# LM3S1150 register map
File version: 7944
Registers are 32-bit, read-write, no defined reset value unless marked. A register's access mark holds for its fields unless they carry their own. Offsets are from the block's base; [hi:lo] are bit positions; {n}, {i} and the like mark numbered series.

## QEI0 — Register map for QEI0 peripheral
Base 0x4002C000; register names take the prefix QEI0
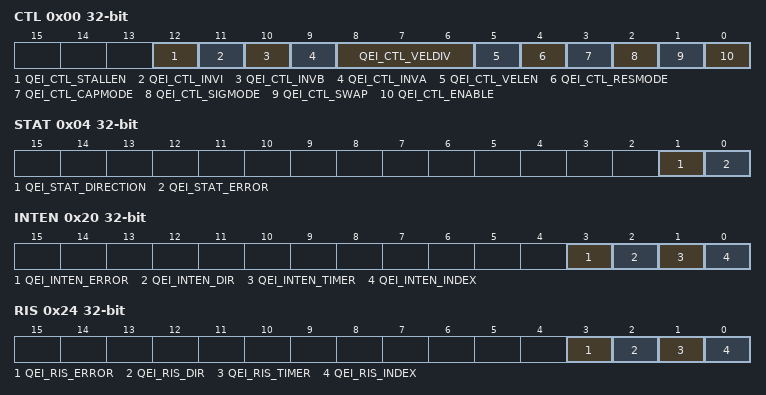
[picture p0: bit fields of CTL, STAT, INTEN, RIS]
0x00 CTL — QEI Control
  [12] QEI_CTL_STALLEN — Stall QEI
  [11] QEI_CTL_INVI — Invert Index Pulse
  [10] QEI_CTL_INVB — Invert PhB
  [9] QEI_CTL_INVA — Invert PhA
  [8:6] QEI_CTL_VELDIV — Predivide Velocity
    0=QEI clock /1; 1=QEI clock /2; 2=QEI clock /4; 3=QEI clock /8; 4=QEI clock /16; 5=QEI clock /32; 6=QEI clock /64; 7=QEI clock /128
  [5] QEI_CTL_VELEN — Capture Velocity
  [4] QEI_CTL_RESMODE — Reset Mode
  [3] QEI_CTL_CAPMODE — Capture Mode
  [2] QEI_CTL_SIGMODE — Signal Mode
  [1] QEI_CTL_SWAP — Swap Signals
  [0] QEI_CTL_ENABLE — Enable QEI
0x04 STAT — QEI Status
  [1] QEI_STAT_DIRECTION — Direction of Rotation
  [0] QEI_STAT_ERROR — Error Detected
0x08 POS — QEI Position
  [31:0] QEI_POS — Current Position Integrator Value
0x0C MAXPOS — QEI Maximum Position
  [31:0] QEI_MAXPOS — Maximum Position Integrator Value
0x10 LOAD — QEI Timer Load
  [31:0] QEI_LOAD — Velocity Timer Load Value
0x14 TIME — QEI Timer
  [31:0] QEI_TIME — Velocity Timer Current Value
0x18 COUNT — QEI Velocity Counter
  [31:0] QEI_COUNT — Velocity Pulse Count
0x1C SPEED — QEI Velocity
  [31:0] QEI_SPEED — Velocity
0x20 INTEN — QEI Interrupt Enable
  [3] QEI_INTEN_ERROR — Phase Error Interrupt Enable
  [2] QEI_INTEN_DIR — Direction Change Interrupt Enable
  [1] QEI_INTEN_TIMER — Timer Expires Interrupt Enable
  [0] QEI_INTEN_INDEX — Index Pulse Detected Interrupt Enable
0x24 RIS — QEI Raw Interrupt Status
  [3] QEI_RIS_ERROR — Phase Error Detected
  [2] QEI_RIS_DIR — Direction Change Detected
  [1] QEI_RIS_TIMER — Velocity Timer Expired
  [0] QEI_RIS_INDEX — Index Pulse Asserted
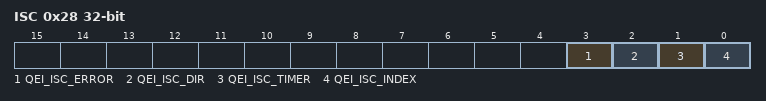
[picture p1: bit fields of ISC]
0x28 ISC — QEI Interrupt Status and Clear
  [3] QEI_ISC_ERROR — Phase Error Interrupt
  [2] QEI_ISC_DIR — Direction Change Interrupt
  [1] QEI_ISC_TIMER — Velocity Timer Expired Interrupt
  [0] QEI_ISC_INDEX — Index Pulse Interrupt

## COMP — Register map for COMP peripheral
Base 0x4003C000; register names take the prefix COMP
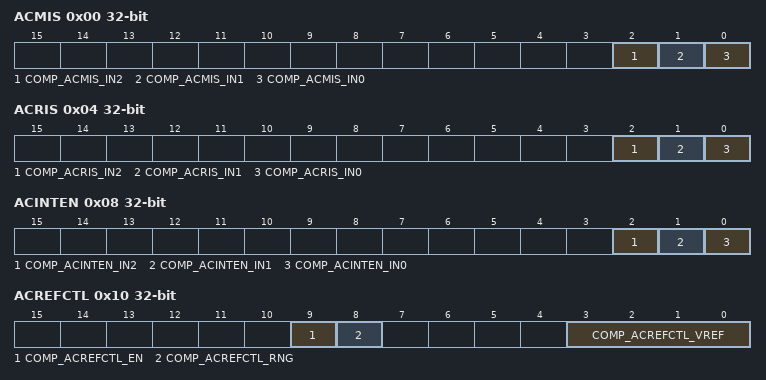
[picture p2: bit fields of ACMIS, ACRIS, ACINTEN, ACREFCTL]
0x00 ACMIS — Analog Comparator Masked Interrupt Status
  [2] COMP_ACMIS_IN2 — Comparator 2 Masked Interrupt Status
  [1] COMP_ACMIS_IN1 — Comparator 1 Masked Interrupt Status
  [0] COMP_ACMIS_IN0 — Comparator 0 Masked Interrupt Status
0x04 ACRIS — Analog Comparator Raw Interrupt Status
  [2] COMP_ACRIS_IN2 — Comparator 2 Interrupt Status
  [1] COMP_ACRIS_IN1 — Comparator 1 Interrupt Status
  [0] COMP_ACRIS_IN0 — Comparator 0 Interrupt Status
0x08 ACINTEN — Analog Comparator Interrupt Enable
  [2] COMP_ACINTEN_IN2 — Comparator 2 Interrupt Enable
  [1] COMP_ACINTEN_IN1 — Comparator 1 Interrupt Enable
  [0] COMP_ACINTEN_IN0 — Comparator 0 Interrupt Enable
0x10 ACREFCTL — Analog Comparator Reference Voltage Control
  [9] COMP_ACREFCTL_EN — Resistor Ladder Enable
  [8] COMP_ACREFCTL_RNG — Resistor Ladder Range
  [3:0] COMP_ACREFCTL_VREF — Resistor Ladder Voltage Ref
{0x20+0x20*i} ACSTAT{i} (i=0..2) — Analog Comparator Status {i}
  [1] COMP_ACSTAT{i}_OVAL — Comparator Output Value
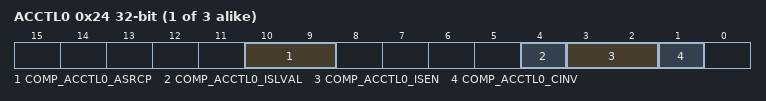
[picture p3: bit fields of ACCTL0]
{0x24+0x20*i} ACCTL{i} (i=0..2) — Analog Comparator Control {i}
  [10:9] COMP_ACCTL{i}_ASRCP — Analog Source Positive
    0=COMP_ACCTL{i}_ASRCP_PIN (Pin value of Cn+); 1=COMP_ACCTL{i}_ASRCP_PIN0 (Pin value of C0+); 2=COMP_ACCTL{i}_ASRCP_REF (Internal voltage reference (VIREF))
  [4] COMP_ACCTL{i}_ISLVAL — Interrupt Sense Level Value
  [3:2] COMP_ACCTL{i}_ISEN — Interrupt Sense
    0=COMP_ACCTL{i}_ISEN_LEVEL (Level sense, see ISLVAL); 1=COMP_ACCTL{i}_ISEN_FALL (Falling edge); 2=COMP_ACCTL{i}_ISEN_RISE (Rising edge); 3=COMP_ACCTL{i}_ISEN_BOTH (Either edge)
  [1] COMP_ACCTL{i}_CINV — Comparator Output Invert

## HIB — Register map for HIB peripheral
Base 0x400FC000; register names take the prefix HIB
0x00 RTCC — Hibernation RTC Counter
  [31:0] HIB_RTCC — RTC Counter
0x04 RTCM0 — Hibernation RTC Match 0
  [31:0] HIB_RTCM0 — RTC Match 0
0x08 RTCM1 — Hibernation RTC Match 1
  [31:0] HIB_RTCM1 — RTC Match 1
0x0C RTCLD — Hibernation RTC Load
  [31:0] HIB_RTCLD — RTC Load
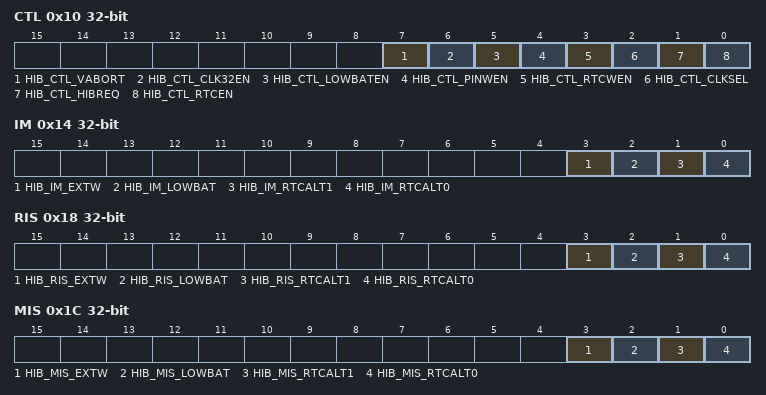
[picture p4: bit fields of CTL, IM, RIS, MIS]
0x10 CTL — Hibernation Control
  [7] HIB_CTL_VABORT — Power Cut Abort Enable
  [6] HIB_CTL_CLK32EN — Clocking Enable
  [5] HIB_CTL_LOWBATEN — Low Battery Monitoring Enable
  [4] HIB_CTL_PINWEN — External WAKE Pin Enable
  [3] HIB_CTL_RTCWEN — RTC Wake-up Enable
  [2] HIB_CTL_CLKSEL — Hibernation Module Clock Select
  [1] HIB_CTL_HIBREQ — Hibernation Request
  [0] HIB_CTL_RTCEN — RTC Timer Enable
0x14 IM — Hibernation Interrupt Mask
  [3] HIB_IM_EXTW — External Wake-Up Interrupt Mask
  [2] HIB_IM_LOWBAT — Low Battery Voltage Interrupt Mask
  [1] HIB_IM_RTCALT1 — RTC Alert 1 Interrupt Mask
  [0] HIB_IM_RTCALT0 — RTC Alert 0 Interrupt Mask
0x18 RIS — Hibernation Raw Interrupt Status
  [3] HIB_RIS_EXTW — External Wake-Up Raw Interrupt Status
  [2] HIB_RIS_LOWBAT — Low Battery Voltage Raw Interrupt Status
  [1] HIB_RIS_RTCALT1 — RTC Alert 1 Raw Interrupt Status
  [0] HIB_RIS_RTCALT0 — RTC Alert 0 Raw Interrupt Status
0x1C MIS — Hibernation Masked Interrupt Status
  [3] HIB_MIS_EXTW — External Wake-Up Masked Interrupt Status
  [2] HIB_MIS_LOWBAT — Low Battery Voltage Masked Interrupt Status
  [1] HIB_MIS_RTCALT1 — RTC Alert 1 Masked Interrupt Status
  [0] HIB_MIS_RTCALT0 — RTC Alert 0 Masked Interrupt Status
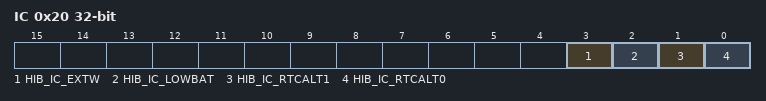
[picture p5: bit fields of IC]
0x20 IC — Hibernation Interrupt Clear
  [3] HIB_IC_EXTW — External Wake-Up Masked Interrupt Clear
  [2] HIB_IC_LOWBAT — Low Battery Voltage Masked Interrupt Clear
  [1] HIB_IC_RTCALT1 — RTC Alert1 Masked Interrupt Clear
  [0] HIB_IC_RTCALT0 — RTC Alert0 Masked Interrupt Clear
0x24 RTCT — Hibernation RTC Trim
  [15:0] HIB_RTCT_TRIM — RTC Trim Value
0x30 DATA — Hibernation Data
  [31:0] HIB_DATA_RTD — Hibernation Module NV Data

## FLASH_CTRL — Register map for FLASH_CTRL peripheral
Base 0x400FD000; register names take the prefix FLASH_CTRL
0x00 FMA — Flash Memory Address
  [15:0] FLASH_FMA_OFFSET — Address Offset
0x04 FMD — Flash Memory Data
  [31:0] FLASH_FMD_DATA — Data Value
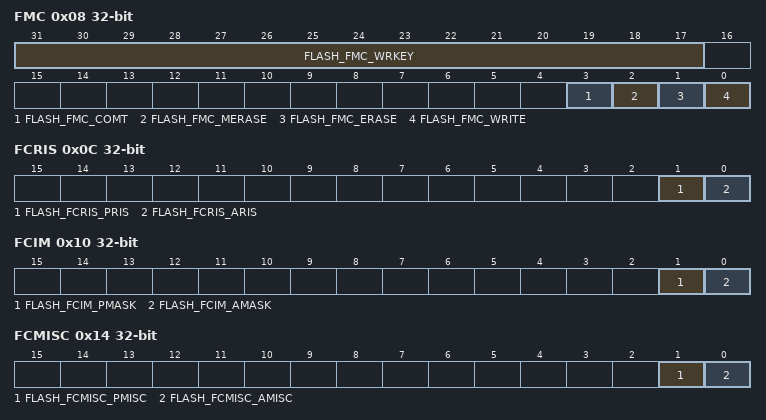
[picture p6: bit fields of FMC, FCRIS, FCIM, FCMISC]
0x08 FMC — Flash Memory Control
  [31:17] FLASH_FMC_WRKEY — FLASH write key
  [3] FLASH_FMC_COMT — Commit Register Value
  [2] FLASH_FMC_MERASE — Mass Erase Flash Memory
  [1] FLASH_FMC_ERASE — Erase a Page of Flash Memory
  [0] FLASH_FMC_WRITE — Write a Word into Flash Memory
0x0C FCRIS — Flash Controller Raw Interrupt Status
  [1] FLASH_FCRIS_PRIS — Programming Raw Interrupt Status
  [0] FLASH_FCRIS_ARIS — Access Raw Interrupt Status
0x10 FCIM — Flash Controller Interrupt Mask
  [1] FLASH_FCIM_PMASK — Programming Interrupt Mask
  [0] FLASH_FCIM_AMASK — Access Interrupt Mask
0x14 FCMISC — Flash Controller Masked Interrupt Status and Clear
  [1] FLASH_FCMISC_PMISC — Programming Masked Interrupt Status and Clear
  [0] FLASH_FCMISC_AMISC — Access Masked Interrupt Status and Clear
0x1140 USECRL — USec Reload
  [7:0] FLASH_USECRL — Microsecond Reload Value
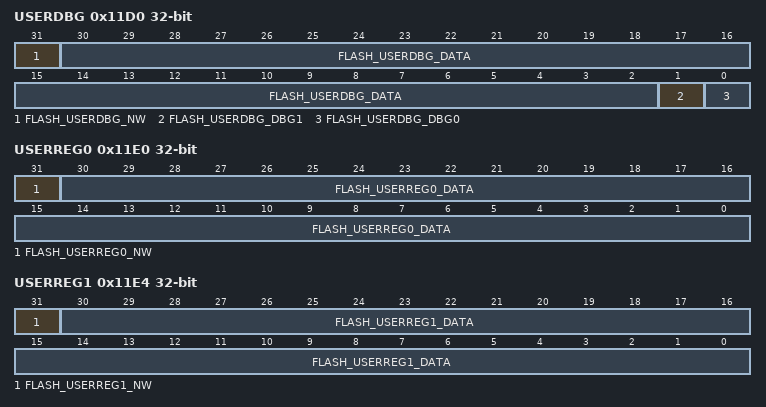
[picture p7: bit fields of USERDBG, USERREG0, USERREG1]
0x11D0 USERDBG (FLASH_ALT view) — User Debug
  [31] FLASH_USERDBG_NW — User Debug Not Written
  [30:2] FLASH_USERDBG_DATA — User Data
  [1] FLASH_USERDBG_DBG1 — Debug Control 1
  [0] FLASH_USERDBG_DBG0 — Debug Control 0
0x11E0 USERREG0 — User Register 0
  [31] FLASH_USERREG0_NW — Not Written
  [30:0] FLASH_USERREG0_DATA — User Data
0x11E4 USERREG1 — User Register 1
  [31] FLASH_USERREG1_NW — Not Written
  [30:0] FLASH_USERREG1_DATA — User Data
{0x1200+4i} FMPRE{i} (i=0..3) — Flash Memory Protection Read Enable {i}
{0x1400+4i} FMPPE{i} (i=0..3) — Flash Memory Protection Program Enable {i}
